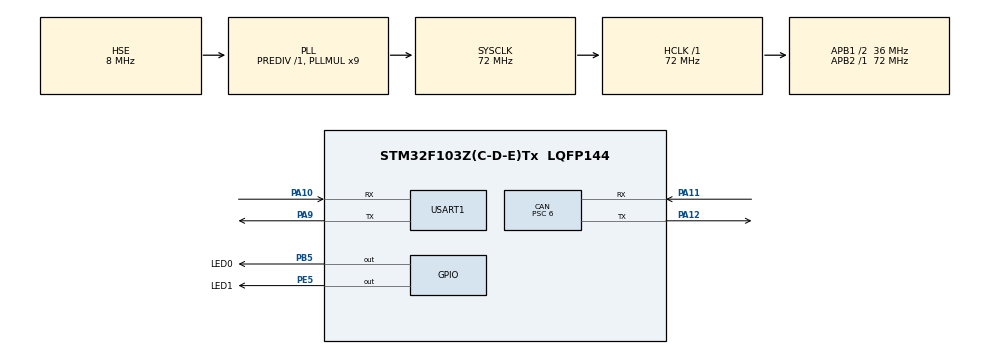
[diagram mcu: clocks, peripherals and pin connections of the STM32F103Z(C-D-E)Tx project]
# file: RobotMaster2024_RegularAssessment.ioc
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CAN.BS1=CAN_BS1_4TQ
CAN.BS2=CAN_BS2_2TQ
CAN.CalculateBaudRate=857142
CAN.CalculateTimeBit=1166
CAN.CalculateTimeQuantum=166.66666666666669
CAN.Prescaler=6
Dma.Request0=USART1_RX
Dma.Request1=USART1_TX
Dma.USART1_RX.0.Direction=DMA_PERIPH_TO_MEMORY
Dma.USART1_RX.0.Instance=DMA1_Channel5
Dma.USART1_RX.0.MemDataAlignment=DMA_MDATAALIGN_BYTE
Dma.USART1_RX.0.MemInc=DMA_MINC_ENABLE
Dma.USART1_RX.0.Mode=DMA_NORMAL
Dma.USART1_RX.0.PeriphDataAlignment=DMA_PDATAALIGN_BYTE
Dma.USART1_RX.0.PeriphInc=DMA_PINC_DISABLE
Dma.USART1_RX.0.Priority=DMA_PRIORITY_LOW
Dma.USART1_TX.1.Direction=DMA_MEMORY_TO_PERIPH
Dma.USART1_TX.1.Instance=DMA1_Channel4
Dma.USART1_TX.1.MemDataAlignment=DMA_MDATAALIGN_BYTE
Dma.USART1_TX.1.MemInc=DMA_MINC_ENABLE
Dma.USART1_TX.1.Mode=DMA_NORMAL
Dma.USART1_TX.1.PeriphDataAlignment=DMA_PDATAALIGN_BYTE
Dma.USART1_TX.1.PeriphInc=DMA_PINC_DISABLE
Dma.USART1_TX.1.Priority=DMA_PRIORITY_LOW
FREERTOS.INCLUDE_xTaskGetCurrentTaskHandle=1
FREERTOS.Tasks01=defaultTask,24,128,StartDefaultTask,Default,NULL,Dynamic,NULL,NULL;LED0_Toggle,8,128,LED0_Toggle_Start,Default,NULL,Dynamic,NULL,NULL;LED1_Toggle,11,128,LED1_Toggle_Start,Default,NULL,Dynamic,NULL,NULL
FREERTOS.configUSE_NEWLIB_REENTRANT=0
FREERTOS.copyHeapFile=0
Mcu.Family=STM32F1
Mcu.Name=STM32F103Z(C-D-E)Tx
Mcu.Package=LQFP144
NVIC.CAN1_RX1_IRQn=true\:5\:0\:false\:false\:true\:true\:true\:true\:true
NVIC.CAN1_SCE_IRQn=true\:5\:0\:false\:false\:true\:true\:true\:true\:true
NVIC.DMA1_Channel4_IRQn=true\:5\:0\:false\:false\:true\:true\:false\:true\:true
NVIC.DMA1_Channel5_IRQn=true\:5\:0\:false\:false\:true\:true\:false\:true\:true
NVIC.PriorityGroup=NVIC_PRIORITYGROUP_4
NVIC.TIM1_UP_IRQn=true\:15\:0\:false\:false\:true\:false\:false\:true\:true
NVIC.TimeBase=TIM1_UP_IRQn
NVIC.TimeBaseIP=TIM1
NVIC.USART1_IRQn=true\:5\:0\:false\:true\:true\:1\:true\:true\:true\:true
NVIC.USB_HP_CAN1_TX_IRQn=true\:5\:0\:false\:false\:true\:true\:true\:true\:true
NVIC.USB_LP_CAN1_RX0_IRQn=true\:5\:0\:false\:false\:true\:true\:true\:true\:true
OSC_IN.Mode=HSE-External-Oscillator
OSC_IN.Signal=RCC_OSC_IN
OSC_OUT.Mode=HSE-External-Oscillator
OSC_OUT.Signal=RCC_OSC_OUT
PA10.Mode=Asynchronous
PA10.Signal=USART1_RX
PA11.Mode=CAN_Activate
PA11.Signal=CAN_RX
PA12.Mode=CAN_Activate
PA12.Signal=CAN_TX
PA13.Mode=Serial_Wire
PA13.Signal=SYS_JTMS-SWDIO
PA14.Mode=Serial_Wire
PA14.Signal=SYS_JTCK-SWCLK
PA9.Mode=Asynchronous
PA9.Signal=USART1_TX
PB5.GPIO_Label=LED0
PB5.Signal=GPIO_Output
PC14-OSC32_IN.Mode=LSE-External-Oscillator
PC14-OSC32_IN.Signal=RCC_OSC32_IN
PC15-OSC32_OUT.Mode=LSE-External-Oscillator
PC15-OSC32_OUT.Signal=RCC_OSC32_OUT
PE5.GPIO_Label=LED1
PE5.Signal=GPIO_Output
ProjectManager.HeapSize=0x200
ProjectManager.StackSize=0x400
ProjectManager.TargetToolchain=MDK-ARM V5.32
RCC.AHBFreq_Value=72000000
RCC.APB1CLKDivider=RCC_HCLK_DIV2
RCC.APB1Freq_Value=36000000
RCC.APB1TimFreq_Value=72000000
RCC.APB2Freq_Value=72000000
RCC.APB2TimFreq_Value=72000000
RCC.HCLKFreq_Value=72000000
RCC.PLLMUL=RCC_PLL_MUL9
RCC.PLLSourceVirtual=RCC_PLLSOURCE_HSE
RCC.SYSCLKFreq_VALUE=72000000
RCC.SYSCLKSource=RCC_SYSCLKSOURCE_PLLCLK
RCC.USBFreq_Value=72000000
USART1.VirtualMode=VM_ASYNC
VP_FREERTOS_VS_CMSIS_V2.Mode=CMSIS_V2
VP_SYS_VS_tim1.Mode=TIM1
board=custom

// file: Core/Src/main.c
/* USER CODE BEGIN Header */
/**
 ******************************************************************************
 * @file           : main.c
 * @brief          : Main program body
 ******************************************************************************
 * @attention
 *
 * Copyright (c) 2024 STMicroelectronics.
 * All rights reserved.
 *
 * This software is licensed under terms that can be found in the LICENSE file
 * in the root directory of this software component.
 * If no LICENSE file comes with this software, it is provided AS-IS.
 *
 ******************************************************************************
 */
/* USER CODE END Header */
#include "main.h"
#include "cmsis_os.h"
#include "can.h"
#include "dma.h"
#include "usart.h"
#include "gpio.h"

/* USER CODE BEGIN Includes */
#include "stdio.h"
#include "remote.h"
#include "SEGGER_RTT.h"
#include "trcRecorder.h"
/* USER CODE END Includes */

/* USER CODE BEGIN PV */
uint8_t receivedata[2];
/* USER CODE END PV */

void SystemClock_Config(void);
void MX_FREERTOS_Init(void);
static void MX_NVIC_Init(void);

int main(void)
{

  /* MCU Configuration--------------------------------------------------------*/

  /* Reset of all peripherals, Initializes the Flash interface and the Systick. */
  HAL_Init();

  /* Configure the system clock */
  SystemClock_Config();

  /* USER CODE BEGIN SysInit */
  vTraceEnable(TRC_START);

  /* USER CODE END SysInit */

  /* Initialize all configured peripherals */
  MX_GPIO_Init();
  MX_DMA_Init();
  MX_USART1_UART_Init();
  MX_CAN_Init();

  /* Initialize interrupts */
  MX_NVIC_Init();
  /* USER CODE BEGIN 2 */

  SEGGER_RTT_Init();

  // HAL_UART_Receive_DMA(&huart1, rx_buffer, 2);
  HAL_UARTEx_ReceiveToIdle_DMA(&huart1, rx_buffer, sizeof(rx_buffer));
  /* USER CODE END 2 */

  /* Init scheduler */
  osKernelInitialize();

  /* Call init function for freertos objects (in freertos.c) */
  MX_FREERTOS_Init();

  /* Start scheduler */
  osKernelStart();

  /* We should never get here as control is now taken by the scheduler */
  /* Infinite loop */
  while (1)
  {

    /* USER CODE BEGIN 3 */

    //HAL_UART_Transmit_IT(&huart1, receivedata, 2);

    // HAL_Delay(1000);
    // HAL_UART_Transmit(&huart1,"1234", 4, 100);
  }
  /* USER CODE END 3 */
}

void SystemClock_Config(void)
{
  RCC_OscInitTypeDef RCC_OscInitStruct = {0};
  RCC_ClkInitTypeDef RCC_ClkInitStruct = {0};

  /** Initializes the RCC Oscillators according to the specified parameters
  * in the RCC_OscInitTypeDef structure.
  */
  RCC_OscInitStruct.OscillatorType = RCC_OSCILLATORTYPE_HSE;
  RCC_OscInitStruct.HSEState = RCC_HSE_ON;
  RCC_OscInitStruct.HSEPredivValue = RCC_HSE_PREDIV_DIV1;
  RCC_OscInitStruct.HSIState = RCC_HSI_ON;
  RCC_OscInitStruct.PLL.PLLState = RCC_PLL_ON;
  RCC_OscInitStruct.PLL.PLLSource = RCC_PLLSOURCE_HSE;
  RCC_OscInitStruct.PLL.PLLMUL = RCC_PLL_MUL9;
  if (HAL_RCC_OscConfig(&RCC_OscInitStruct) != HAL_OK)
  {
    Error_Handler();
  }

  /** Initializes the CPU, AHB and APB buses clocks
  */
  RCC_ClkInitStruct.ClockType = RCC_CLOCKTYPE_HCLK|RCC_CLOCKTYPE_SYSCLK
                              |RCC_CLOCKTYPE_PCLK1|RCC_CLOCKTYPE_PCLK2;
  RCC_ClkInitStruct.SYSCLKSource = RCC_SYSCLKSOURCE_PLLCLK;
  RCC_ClkInitStruct.AHBCLKDivider = RCC_SYSCLK_DIV1;
  RCC_ClkInitStruct.APB1CLKDivider = RCC_HCLK_DIV2;
  RCC_ClkInitStruct.APB2CLKDivider = RCC_HCLK_DIV1;

  if (HAL_RCC_ClockConfig(&RCC_ClkInitStruct, FLASH_LATENCY_2) != HAL_OK)
  {
    Error_Handler();
  }
}

/**
  * @brief NVIC Configuration.
  * @retval None
  */
static void MX_NVIC_Init(void)
{
  /* USART1_IRQn interrupt configuration */
  HAL_NVIC_SetPriority(USART1_IRQn, 5, 0);
  HAL_NVIC_EnableIRQ(USART1_IRQn);
}

void HAL_TIM_PeriodElapsedCallback(TIM_HandleTypeDef *htim)
{
  if (htim->Instance == TIM1) {
    HAL_IncTick();
  }
}

void Error_Handler(void)
{
  __disable_irq();
  while (1)
  {
  }
}

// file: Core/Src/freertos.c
/* USER CODE BEGIN Header */
/**
  ******************************************************************************
  * File Name          : freertos.c
  * Description        : Code for freertos applications
  ******************************************************************************
  * @attention
  *
  * Copyright (c) 2024 STMicroelectronics.
  * All rights reserved.
  *
  * This software is licensed under terms that can be found in the LICENSE file
  * in the root directory of this software component.
  * If no LICENSE file comes with this software, it is provided AS-IS.
  *
  ******************************************************************************
  */
/* USER CODE END Header */

#include "FreeRTOS.h"
#include "task.h"
#include "main.h"
#include "cmsis_os.h"

/* USER CODE BEGIN Includes */
#include "SEGGER_RTT.h"
/* USER CODE END Includes */

/* Definitions for defaultTask */
osThreadId_t defaultTaskHandle;
const osThreadAttr_t defaultTask_attributes = {
  .name = "defaultTask",
  .stack_size = 128 * 4,
  .priority = (osPriority_t) osPriorityNormal,
};
/* Definitions for LED0_Toggle */
osThreadId_t LED0_ToggleHandle;
const osThreadAttr_t LED0_Toggle_attributes = {
  .name = "LED0_Toggle",
  .stack_size = 128 * 4,
  .priority = (osPriority_t) osPriorityLow,
};
/* Definitions for LED1_Toggle */
osThreadId_t LED1_ToggleHandle;
const osThreadAttr_t LED1_Toggle_attributes = {
  .name = "LED1_Toggle",
  .stack_size = 128 * 4,
  .priority = (osPriority_t) osPriorityLow3,
};

void StartDefaultTask(void *argument);
void LED0_Toggle_Start(void *argument);
void LED1_Toggle_Start(void *argument);

void MX_FREERTOS_Init(void); /* (MISRA C 2004 rule 8.1) */

void MX_FREERTOS_Init(void) {

  /* Create the thread(s) */
  /* creation of defaultTask */
  defaultTaskHandle = osThreadNew(StartDefaultTask, NULL, &defaultTask_attributes);

  /* creation of LED0_Toggle */
  LED0_ToggleHandle = osThreadNew(LED0_Toggle_Start, NULL, &LED0_Toggle_attributes);

  /* creation of LED1_Toggle */
  LED1_ToggleHandle = osThreadNew(LED1_Toggle_Start, NULL, &LED1_Toggle_attributes);

}

void StartDefaultTask(void *argument)
{
  for(;;)
  {
    osDelay(1);
  }
}

void LED0_Toggle_Start(void *argument)
{
  /* USER CODE BEGIN LED0_Toggle_Start */
  /* Infinite loop */
  for(;;)
  {
    osDelay(100);
    HAL_GPIO_TogglePin(LED0_GPIO_Port,LED0_Pin);
  }
  /* USER CODE END LED0_Toggle_Start */
}

void LED1_Toggle_Start(void *argument)
{
  /* USER CODE BEGIN LED1_Toggle_Start */
  /* Infinite loop */
  for(;;)
  {
	HAL_GPIO_TogglePin(LED1_GPIO_Port,LED1_Pin);
    osDelay(1000);

  }
  /* USER CODE END LED1_Toggle_Start */
}
